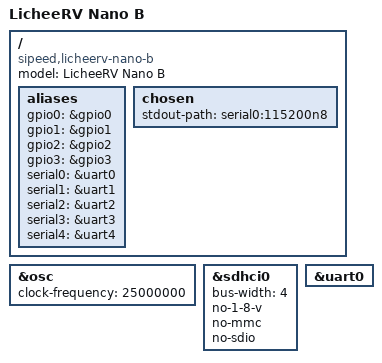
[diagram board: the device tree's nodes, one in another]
// SPDX-License-Identifier: (GPL-2.0 OR MIT)
/*
 * Copyright (C) 2024 Thomas Bonnefille <thomas.bonnefille@bootlin.com>
 */

/dts-v1/;

#include "sg2002.dtsi"

/ {
	model = "LicheeRV Nano B";
	compatible = "sipeed,licheerv-nano-b", "sipeed,licheerv-nano", "sophgo,sg2002";

	aliases {
		gpio0 = &gpio0;
		gpio1 = &gpio1;
		gpio2 = &gpio2;
		gpio3 = &gpio3;
		serial0 = &uart0;
		serial1 = &uart1;
		serial2 = &uart2;
		serial3 = &uart3;
		serial4 = &uart4;
	};

	chosen {
		stdout-path = "serial0:115200n8";
	};
};

&osc {
	clock-frequency = <25000000>;
};

&sdhci0 {
	status = "okay";
	bus-width = <4>;
	no-1-8-v;
	no-mmc;
	no-sdio;
};

&uart0 {
	status = "okay";
};
